# CY8C5868AXI_LP032 register map
File version: 0.1
CY8C58LP
Registers are 8-bit, read-write, no defined reset value unless marked. A register's access mark holds for its fields unless they carry their own. Offsets are from the block's base; lines under a group give offsets from that group; [hi:lo] are bit positions; {n}, {i} and the like mark numbered series; 'fields as' and 'values as' point back to an identical list; <NAME> marks a mode.

## Memory map
0x40004320 BoostConv size 0x7
0x400043A3 Divider size 0xB64
0x400043A4 TIA size 0x179E
0x400043A4 Drive size 0x17A0
0x400043A7 Clipping_Sense size 0x17F0
0x400043A8 IDrive size 0x17DC
0x400043AA ADC size 0x17E0
0x40004616 ResistiveTouch_1_ADC_SAR size 0x158D — SAR ADC
0x40006474 LCD_LCD_Control size 0x1
0x40006475 SOC_Go size 0x1
0x40006525 PWM_1 size 0x71
0x40006564 Status_Reg size 0x31
0x40006574 Phase size 0x1

## PWM_1
Base 0x40006525
0x00 PWM_1_COMPARE_Reg_ — UDB.D0 - Assigned Compare Value
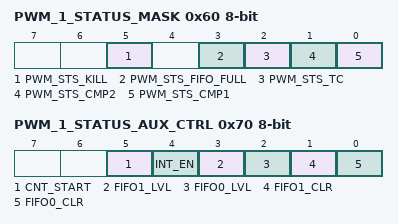
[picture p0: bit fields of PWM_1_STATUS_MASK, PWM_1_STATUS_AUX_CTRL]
0x60 PWM_1_STATUS_MASK — UDB Status bits Interrupt Mask Enable Register
  [5] PWM_STS_KILL ro — Enables the Interrupt on Kill
  [3] PWM_STS_FIFO_FULL ro — FIFO Full Status Mask
  [2] PWM_STS_TC ro — Enables the Interrupt on Terminal Count
  [1] PWM_STS_CMP2 ro — Enables the Interrupt on Compare 2
  [0] PWM_STS_CMP1 ro — Enables the Interrupt on Compare 1
0x70 PWM_1_STATUS_AUX_CTRL — UDB Auxilliary Control Register
  [5] CNT_START — FIFO0 clear
    0=E_CNT_START0 (Disable counter); 1=E_CNT_START1 (Enable counter)
  [4] INT_EN
    0=E_INT_EN0 (Interrupt disabled); 1=E_INT_EN1 (Interrupt enabled)
  [3] FIFO1_LVL — FIFO level
    0=E_FIFO_LVL_0 (FIFO LVL: input mode: FIFO not full; output mode: FIFO not empty); 1=E_FIFO_LVL_1 (FIFO LVL: input mode: FIFO at least 1/2 empty; output mode: FIFO at least 1/2 full)
  [2] FIFO0_LVL — FIFO level
    values as FIFO1_LVL
  [1] FIFO1_CLR — FIFO1 clear
    0=E_FIFO_CLR_0 (Normal FIFO operation); 1=E_FIFO_CLR_1 (Clear FIFO state)
  [0] FIFO0_CLR — FIFO0 clear
    values as FIFO1_CLR

## ResistiveTouch_1_ADC_SAR — SAR ADC
Base 0x40004616
0x00 SAR_TR0 — SAR trim register
{0x12F2+i} SAR_CSR{i} (i=0..6) — SAR status and control register {i}
0x1512 SAR_SW0 — SAR Analog Routing Register 0
{0x1512+i} SAR_SW{i} (i=2..4) — SAR Analog Routing Register {i}
0x1518 SAR_SW6 — SAR Analog Routing Register 6
0x1519 SAR_CLK — SAR Clock Selection Register
0x158C SAR_WRK 16-bit — SAR working register

## LCD_LCD_Control
Base 0x40006474
0x00 LCD_LCD_Control_CONTROL_REG

## Phase
Base 0x40006574
Registers as LCD_LCD_Control (with LCD_LCD_Control read as Phase).

## SOC_Go
Base 0x40006475
Registers as LCD_LCD_Control (with LCD_LCD_Control read as SOC_Go).

## TIA
Base 0x400043A4
0x00 PM_ACT_CFG4 — Active Power Mode Configuration Register 4
  [3:0] EN_OPAMP — Enables subsystems during active power mode
    0=Blk_0 (Enables analog linear output buffer for Opamp block 0); 2=Blk_1 (Enables analog linear output buffer for Opamp block 1); 4=Blk_2 (Enables analog linear output buffer for Opamp block 2); 8=Blk_3 (Enables analog linear output buffer for Opamp block 3)
0x10 PM_STBY_CFG4 — Standby Power Mode Configuration Register 4
  [3:0] EN_OPAMP — Enables subsystems during standby power mode
    values as PM_ACT_CFG4.EN_OPAMP
0x27C OPAMP__TR0 — Analog Output Buffer Trim Register 0
  [4:0] offset_trim — Offset Trim: 420uV typical step size; +/- 6.8mV offset trimmable range
0x27D OPAMP__TR1 — Analog Output Buffer Trim Register 1
0x14B4 OPAMP__CR — Analog Output Buffer Configuration Register
  [1:0] pwr_mode — Power Mode
    0=Default_Fast (Default Power mode Fast); 1=Slow (Power Mode Slow); 2=Medium (Power Mode Medium); 3=Fast (Power Mode Fast)
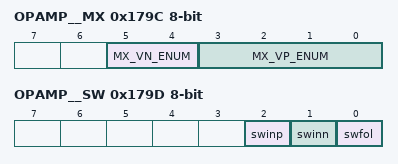
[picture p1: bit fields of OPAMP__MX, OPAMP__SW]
0x179C OPAMP__MX — Analog Buffer Input Selection Register
  [5:4] MX_VN_ENUM — MUX select VN (Negative terminal input)
    0=OPAMP0_MX_VN_DEFAULT (Default - Not Connected (NC)); 1=OPAMP0_MX_VN_AG4 (MUX Selection AGL(4)); 2=OPAMP0_MX_VN_AG6 (MUX Selection AGL(6)); 3=OPAMP0_MX_VN_0x3 (Reserved (NC))
  [3:0] MX_VP_ENUM — MUX select VP (Positive terminal input)
    0=OPAMP0_MX_VP_DEFAULT (Default - Not Connected (NC)); {v}=OPAMP0_MX_VP_AG{v+3} (MUX Selection AGL({v+3})) (v=1..4); {v}=OPAMP0_MX_VP_ABUS{v-5} (MUX Selection ABUSL({v-5})) (v=5..8); 9=OPAMP0_MX_VP_VREF (MUX Selection: OPAMP Voltage Reference); {v}=OPAMP0_MX_VP_H_{0x0+v} (Reserved (NC)) (v=10..15)
0x179D OPAMP__SW — Analog Buffer Routing Switch Register
  [2] swinp — Switch Enable Positive Input
  [1] swinn — Switch Enable Negative Input
  [0] swfol — Switch Enable Follow
